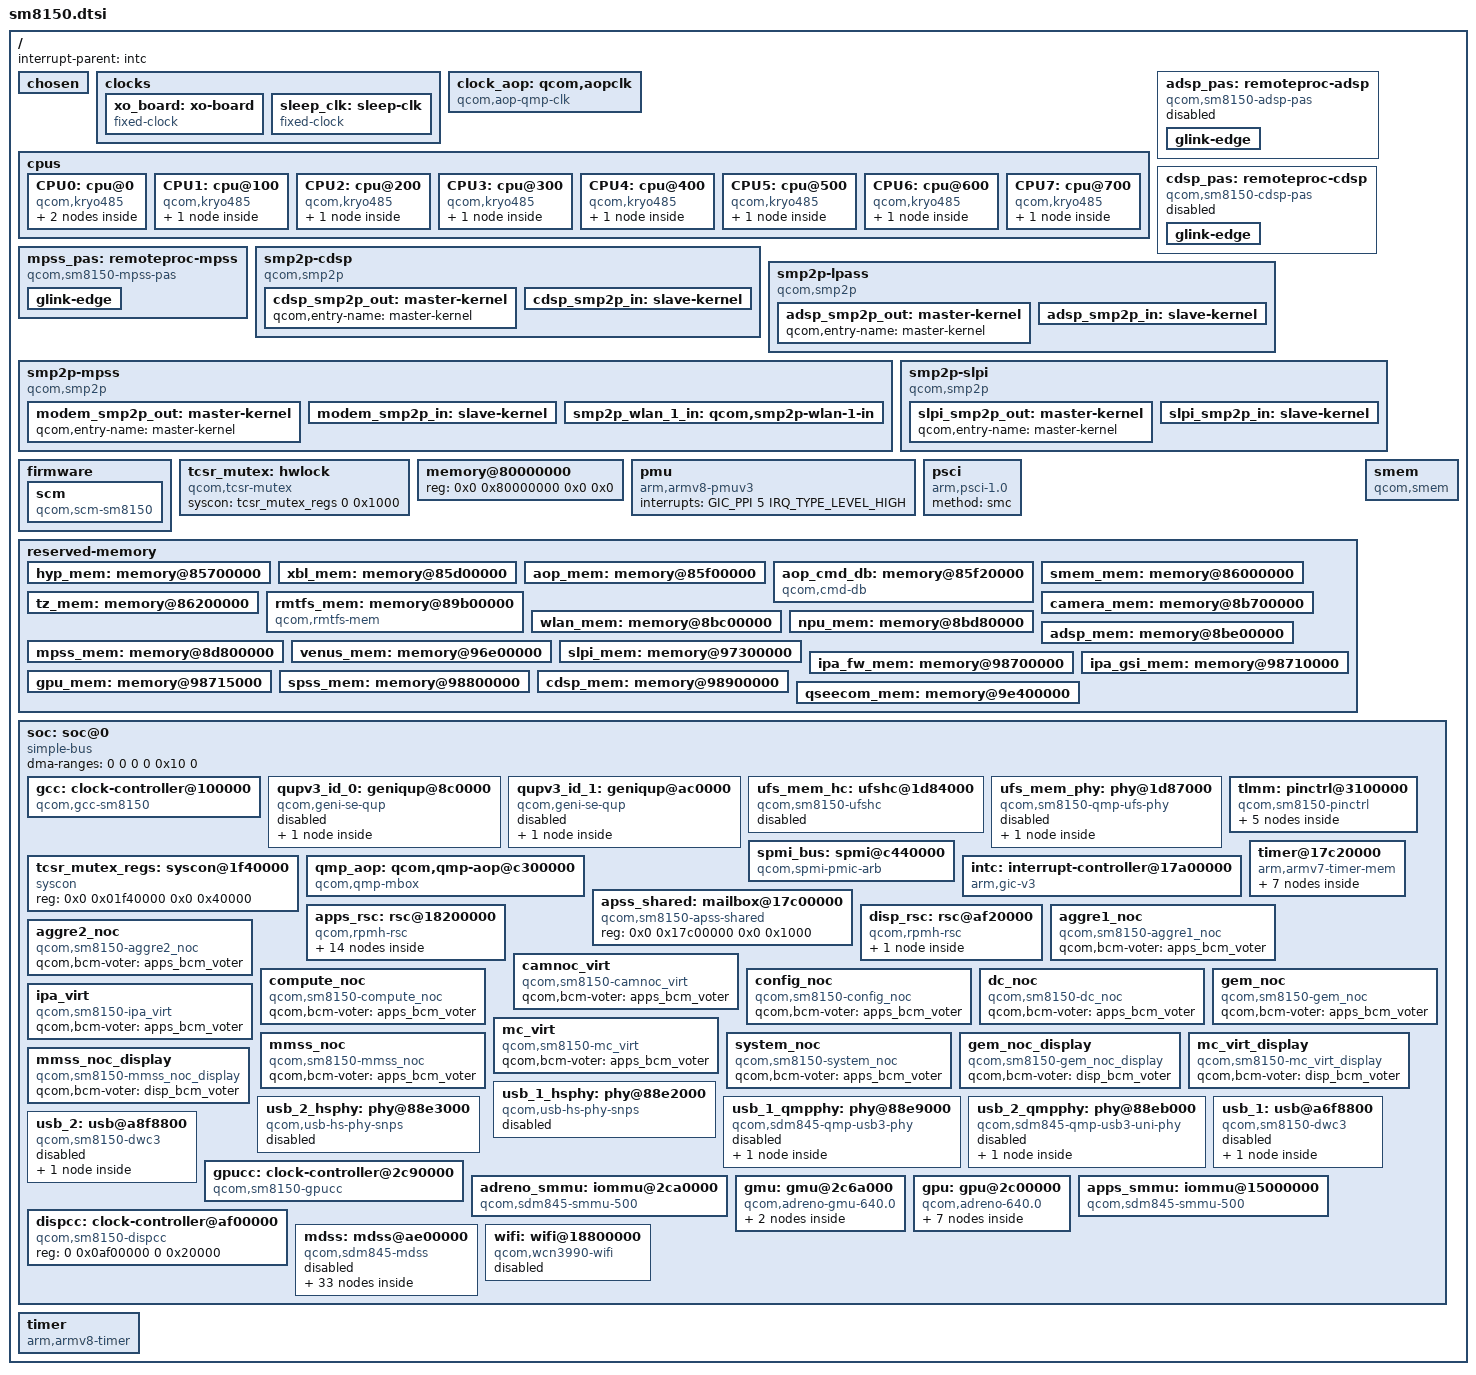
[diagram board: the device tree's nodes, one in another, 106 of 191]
// SPDX-License-Identifier: BSD-3-Clause
/*
 * Copyright (c) 2017-2019, The Linux Foundation. All rights reserved.
 * Copyright (c) 2019, Linaro Limited
 */

#include <dt-bindings/interrupt-controller/arm-gic.h>
#include <dt-bindings/soc/qcom,rpmh-rsc.h>
#include <dt-bindings/clock/qcom,rpmh.h>
#include <dt-bindings/clock/qcom,gcc-sm8150.h>
#include <dt-bindings/clock/qcom,gpucc-sm8150.h>
#include <dt-bindings/clock/qcom,dispcc-sm8150.h>
#include <dt-bindings/power/qcom-rpmpd.h>
#include <dt-bindings/interconnect/qcom,sm8150.h>

/ {
	interrupt-parent = <&intc>;

	#address-cells = <2>;
	#size-cells = <2>;

	chosen { };

	clocks {
		xo_board: xo-board {
			compatible = "fixed-clock";
			#clock-cells = <0>;
			clock-frequency = <38400000>;
			clock-output-names = "xo_board";
		};

		sleep_clk: sleep-clk {
			compatible = "fixed-clock";
			#clock-cells = <0>;
			clock-frequency = <32764>;
			clock-output-names = "sleep_clk";
		};
	};

	clock_aop: qcom,aopclk {
		compatible = "qcom,aop-qmp-clk";
		#clock-cells = <1>;
		mboxes = <&qmp_aop 0>;
		mbox-names = "qdss_clk";
	};

	cpus {
		#address-cells = <2>;
		#size-cells = <0>;

		CPU0: cpu@0 {
			device_type = "cpu";
			compatible = "qcom,kryo485";
			reg = <0x0 0x0>;
			enable-method = "psci";
			next-level-cache = <&L2_0>;
			L2_0: l2-cache {
				compatible = "cache";
				next-level-cache = <&L3_0>;
				L3_0: l3-cache {
				      compatible = "cache";
				};
			};
		};

		CPU1: cpu@100 {
			device_type = "cpu";
			compatible = "qcom,kryo485";
			reg = <0x0 0x100>;
			enable-method = "psci";
			next-level-cache = <&L2_100>;
			L2_100: l2-cache {
				compatible = "cache";
				next-level-cache = <&L3_0>;
			};

		};

		CPU2: cpu@200 {
			device_type = "cpu";
			compatible = "qcom,kryo485";
			reg = <0x0 0x200>;
			enable-method = "psci";
			next-level-cache = <&L2_200>;
			L2_200: l2-cache {
				compatible = "cache";
				next-level-cache = <&L3_0>;
			};
		};

		CPU3: cpu@300 {
			device_type = "cpu";
			compatible = "qcom,kryo485";
			reg = <0x0 0x300>;
			enable-method = "psci";
			next-level-cache = <&L2_300>;
			L2_300: l2-cache {
				compatible = "cache";
				next-level-cache = <&L3_0>;
			};
		};

		CPU4: cpu@400 {
			device_type = "cpu";
			compatible = "qcom,kryo485";
			reg = <0x0 0x400>;
			enable-method = "psci";
			next-level-cache = <&L2_400>;
			L2_400: l2-cache {
				compatible = "cache";
				next-level-cache = <&L3_0>;
			};
		};

		CPU5: cpu@500 {
			device_type = "cpu";
			compatible = "qcom,kryo485";
			reg = <0x0 0x500>;
			enable-method = "psci";
			next-level-cache = <&L2_500>;
			L2_500: l2-cache {
				compatible = "cache";
				next-level-cache = <&L3_0>;
			};
		};

		CPU6: cpu@600 {
			device_type = "cpu";
			compatible = "qcom,kryo485";
			reg = <0x0 0x600>;
			enable-method = "psci";
			next-level-cache = <&L2_600>;
			L2_600: l2-cache {
				compatible = "cache";
				next-level-cache = <&L3_0>;
			};
		};

		CPU7: cpu@700 {
			device_type = "cpu";
			compatible = "qcom,kryo485";
			reg = <0x0 0x700>;
			enable-method = "psci";
			next-level-cache = <&L2_700>;
			L2_700: l2-cache {
				compatible = "cache";
				next-level-cache = <&L3_0>;
			};
		};
	};

	adsp_pas: remoteproc-adsp {
		compatible = "qcom,sm8150-adsp-pas";

		interrupts-extended = <&intc GIC_SPI 162 IRQ_TYPE_EDGE_RISING>,
				      <&adsp_smp2p_in 0 IRQ_TYPE_EDGE_RISING>,
				      <&adsp_smp2p_in 1 IRQ_TYPE_EDGE_RISING>,
				      <&adsp_smp2p_in 2 IRQ_TYPE_EDGE_RISING>,
				      <&adsp_smp2p_in 3 IRQ_TYPE_EDGE_RISING>;
		interrupt-names = "wdog", "fatal", "ready",
				  "handover", "stop-ack";

		clocks = <&rpmhcc RPMH_CXO_CLK>;
		clock-names = "xo";

		memory-region = <&adsp_mem>;

		status = "disabled";

		qcom,smem-states = <&adsp_smp2p_out 0>;
		qcom,smem-state-names = "stop";

		glink-edge {
			interrupts = <GIC_SPI 156 IRQ_TYPE_EDGE_RISING>;
			label = "lpass";
			qcom,remote-pid = <2>;
			mboxes = <&apss_shared 8>;
		};
	};

	cdsp_pas: remoteproc-cdsp {
		compatible = "qcom,sm8150-cdsp-pas";

		interrupts-extended = <&intc GIC_SPI 578 IRQ_TYPE_EDGE_RISING>,
				      <&cdsp_smp2p_in 0 IRQ_TYPE_EDGE_RISING>,
				      <&cdsp_smp2p_in 1 IRQ_TYPE_EDGE_RISING>,
				      <&cdsp_smp2p_in 2 IRQ_TYPE_EDGE_RISING>,
				      <&cdsp_smp2p_in 3 IRQ_TYPE_EDGE_RISING>;
		interrupt-names = "wdog", "fatal", "ready",
				  "handover", "stop-ack";

		clocks = <&rpmhcc RPMH_CXO_CLK>;
		clock-names = "xo";

		memory-region = <&cdsp_mem>;

		status = "disabled";

		qcom,smem-states = <&cdsp_smp2p_out 0>;
		qcom,smem-state-names = "stop";

		glink-edge {
			interrupts = <GIC_SPI 574 IRQ_TYPE_EDGE_RISING>;
			label = "turing";
			qcom,remote-pid = <5>;
			mboxes = <&apss_shared 4>;
		};
	};

	mpss_pas: remoteproc-mpss {
		compatible = "qcom,sm8150-mpss-pas";

		interrupts-extended = <&intc GIC_SPI 266 IRQ_TYPE_EDGE_RISING>,
				      <&modem_smp2p_in 0 IRQ_TYPE_EDGE_RISING>,
				      <&modem_smp2p_in 1 IRQ_TYPE_EDGE_RISING>,
				      <&modem_smp2p_in 2 IRQ_TYPE_EDGE_RISING>,
				      <&modem_smp2p_in 3 IRQ_TYPE_EDGE_RISING>,
				      <&modem_smp2p_in 7 IRQ_TYPE_EDGE_RISING>;
		interrupt-names = "wdog", "fatal", "ready", "handover",
				  "stop-ack", "shutdown-ack";

		clocks = <&rpmhcc RPMH_CXO_CLK>;
		clock-names = "xo";

		memory-region = <&mpss_mem>;

		qcom,smem-states = <&modem_smp2p_out 0>;
		qcom,smem-state-names = "stop";

		glink-edge {
			interrupts = <GIC_SPI 449 IRQ_TYPE_EDGE_RISING>;
			label = "modem";
			qcom,remote-pid = <1>;
			mboxes = <&apss_shared 12>;
		};
	};

	smp2p-cdsp {
		compatible = "qcom,smp2p";
		qcom,smem = <94>, <432>;

		interrupts = <GIC_SPI 576 IRQ_TYPE_EDGE_RISING>;

		mboxes = <&apss_shared 6>;

		qcom,local-pid = <0>;
		qcom,remote-pid = <5>;

		cdsp_smp2p_out: master-kernel {
			qcom,entry-name = "master-kernel";
			#qcom,smem-state-cells = <1>;
		};

		cdsp_smp2p_in: slave-kernel {
			qcom,entry-name = "slave-kernel";

			interrupt-controller;
			#interrupt-cells = <2>;
		};
	};

	smp2p-lpass {
		compatible = "qcom,smp2p";
		qcom,smem = <443>, <429>;

		interrupts = <GIC_SPI 158 IRQ_TYPE_EDGE_RISING>;

		mboxes = <&apss_shared 10>;

		qcom,local-pid = <0>;
		qcom,remote-pid = <2>;

		adsp_smp2p_out: master-kernel {
			qcom,entry-name = "master-kernel";
			#qcom,smem-state-cells = <1>;
		};

		adsp_smp2p_in: slave-kernel {
			qcom,entry-name = "slave-kernel";

			interrupt-controller;
			#interrupt-cells = <2>;
		};
	};

	smp2p-mpss {
		compatible = "qcom,smp2p";
		qcom,smem = <435>, <428>;

		interrupts = <GIC_SPI 451 IRQ_TYPE_EDGE_RISING>;

		mboxes = <&apss_shared 14>;

		qcom,local-pid = <0>;
		qcom,remote-pid = <1>;

		modem_smp2p_out: master-kernel {
			qcom,entry-name = "master-kernel";
			#qcom,smem-state-cells = <1>;
		 };

		modem_smp2p_in: slave-kernel {
			qcom,entry-name = "slave-kernel";

			interrupt-controller;
			#interrupt-cells = <2>;
		};

		smp2p_wlan_1_in: qcom,smp2p-wlan-1-in {
			qcom,entry-name = "wlan";

			interrupt-controller;
			#interrupt-cells = <2>;
		};
	};

	smp2p-slpi {
		compatible = "qcom,smp2p";
		qcom,smem = <481>, <430>;

		interrupts = <GIC_SPI 172 IRQ_TYPE_EDGE_RISING>;

		mboxes = <&apss_shared 26>;

		qcom,local-pid = <0>;
		qcom,remote-pid = <3>;

		slpi_smp2p_out: master-kernel {
			qcom,entry-name = "master-kernel";
			#qcom,smem-state-cells = <1>;
		};

		slpi_smp2p_in: slave-kernel {
			qcom,entry-name = "slave-kernel";

			interrupt-controller;
			#interrupt-cells = <2>;
	       };
	};

	firmware {
		scm: scm {
			compatible = "qcom,scm-sm8150", "qcom,scm";
			#reset-cells = <1>;
		};
	};

	tcsr_mutex: hwlock {
		compatible = "qcom,tcsr-mutex";
		syscon = <&tcsr_mutex_regs 0 0x1000>;
		#hwlock-cells = <1>;
	};

	memory@80000000 {
		device_type = "memory";
		/* We expect the bootloader to fill in the size */
		reg = <0x0 0x80000000 0x0 0x0>;
	};

	pmu {
		compatible = "arm,armv8-pmuv3";
		interrupts = <GIC_PPI 5 IRQ_TYPE_LEVEL_HIGH>;
	};

	psci {
		compatible = "arm,psci-1.0";
		method = "smc";
	};

	reserved-memory {
		#address-cells = <2>;
		#size-cells = <2>;
		ranges;

		hyp_mem: memory@85700000 {
			reg = <0x0 0x85700000 0x0 0x600000>;
			no-map;
		};

		xbl_mem: memory@85d00000 {
			reg = <0x0 0x85d00000 0x0 0x140000>;
			no-map;
		};

		aop_mem: memory@85f00000 {
			reg = <0x0 0x85f00000 0x0 0x20000>;
			no-map;
		};

		aop_cmd_db: memory@85f20000 {
			compatible = "qcom,cmd-db";
			reg = <0x0 0x85f20000 0x0 0x20000>;
			no-map;
		};

		smem_mem: memory@86000000 {
			reg = <0x0 0x86000000 0x0 0x200000>;
			no-map;
		};

		tz_mem: memory@86200000 {
			reg = <0x0 0x86200000 0x0 0x3900000>;
			no-map;
		};

		rmtfs_mem: memory@89b00000 {
			compatible = "qcom,rmtfs-mem";
			reg = <0x0 0x89b00000 0x0 0x200000>;
			no-map;

			qcom,client-id = <1>;
			qcom,vmid = <15>;
		};

		camera_mem: memory@8b700000 {
			reg = <0x0 0x8b700000 0x0 0x500000>;
			no-map;
		};

		wlan_mem: memory@8bc00000 {
			reg = <0x0 0x8bc00000 0x0 0x180000>;
			no-map;
		};

		npu_mem: memory@8bd80000 {
			reg = <0x0 0x8bd80000 0x0 0x80000>;
			no-map;
		};

		adsp_mem: memory@8be00000 {
			reg = <0x0 0x8be00000 0x0 0x1a00000>;
			no-map;
		};

		mpss_mem: memory@8d800000 {
			reg = <0x0 0x8d800000 0x0 0x9600000>;
			no-map;
		};

		venus_mem: memory@96e00000 {
			reg = <0x0 0x96e00000 0x0 0x500000>;
			no-map;
		};

		slpi_mem: memory@97300000 {
			reg = <0x0 0x97300000 0x0 0x1400000>;
			no-map;
		};

		ipa_fw_mem: memory@98700000 {
			reg = <0x0 0x98700000 0x0 0x10000>;
			no-map;
		};

		ipa_gsi_mem: memory@98710000 {
			reg = <0x0 0x98710000 0x0 0x5000>;
			no-map;
		};

		gpu_mem: memory@98715000 {
			reg = <0x0 0x98715000 0x0 0x2000>;
			no-map;
		};

		spss_mem: memory@98800000 {
			reg = <0x0 0x98800000 0x0 0x100000>;
			no-map;
		};

		cdsp_mem: memory@98900000 {
			reg = <0x0 0x98900000 0x0 0x1400000>;
			no-map;
		};

		qseecom_mem: memory@9e400000 {
			reg = <0x0 0x9e400000 0x0 0x1400000>;
			no-map;
		};
	};

	smem {
		compatible = "qcom,smem";
		memory-region = <&smem_mem>;
		hwlocks = <&tcsr_mutex 3>;
	};

	soc: soc@0 {
		#address-cells = <2>;
		#size-cells = <2>;
		ranges = <0 0 0 0 0x10 0>;
		dma-ranges = <0 0 0 0 0x10 0>;
		compatible = "simple-bus";

		gcc: clock-controller@100000 {
			compatible = "qcom,gcc-sm8150";
			reg = <0x0 0x00100000 0x0 0x1f0000>;
			#clock-cells = <1>;
			#reset-cells = <1>;
			#power-domain-cells = <1>;
			clock-names = "bi_tcxo",
				      "sleep_clk";
			clocks = <&rpmhcc RPMH_CXO_CLK>,
				 <&sleep_clk>;
		};

		qupv3_id_0: geniqup@8c0000 {
			compatible = "qcom,geni-se-qup";
			reg = <0x0 0x008c0000 0x0 0x6000>;
			clock-names = "m-ahb", "s-ahb";
			clocks = <&gcc GCC_QUPV3_WRAP_0_M_AHB_CLK>,
				 <&gcc GCC_QUPV3_WRAP_0_S_AHB_CLK>;
			#address-cells = <2>;
			#size-cells = <2>;
			ranges;
			status = "disabled";
			//iommus = <&apps_smmu 0xc3 0x0>;

			i2c4: i2c@890000 {
				compatible = "qcom,geni-i2c";
				reg = <0 0x00890000 0 0x4000>;
				clock-names = "se";
				clocks = <&gcc GCC_QUPV3_WRAP0_S4_CLK>;
				pinctrl-names = "default";
				pinctrl-0 = <&qup_i2c4_default>;
				interrupts = <GIC_SPI 605 IRQ_TYPE_LEVEL_HIGH>;
				#address-cells = <1>;
				#size-cells = <0>;
				status = "disabled";
			};
		};

		qupv3_id_1: geniqup@ac0000 {
			compatible = "qcom,geni-se-qup";
			reg = <0x0 0x00ac0000 0x0 0x6000>;
			clock-names = "m-ahb", "s-ahb";
			clocks = <&gcc GCC_QUPV3_WRAP_1_M_AHB_CLK>,
				 <&gcc GCC_QUPV3_WRAP_1_S_AHB_CLK>;
			#address-cells = <2>;
			#size-cells = <2>;
			ranges;
			status = "disabled";

			uart2: serial@a90000 {
				compatible = "qcom,geni-debug-uart";
				reg = <0x0 0x00a90000 0x0 0x4000>;
				clock-names = "se";
				clocks = <&gcc GCC_QUPV3_WRAP1_S4_CLK>;
				interrupts = <GIC_SPI 357 IRQ_TYPE_LEVEL_HIGH>;
				status = "disabled";
			};
		};

		ufs_mem_hc: ufshc@1d84000 {
			compatible = "qcom,sm8150-ufshc", "qcom,ufshc",
				     "jedec,ufs-2.0";
			reg = <0 0x01d84000 0 0x2500>;
			interrupts = <GIC_SPI 265 IRQ_TYPE_LEVEL_HIGH>;
			phys = <&ufs_mem_phy_lanes>;
			phy-names = "ufsphy";
			lanes-per-direction = <2>;
			#reset-cells = <1>;
			resets = <&gcc GCC_UFS_PHY_BCR>;
			reset-names = "rst";

			clock-names =
				"core_clk",
				"bus_aggr_clk",
				"iface_clk",
				"core_clk_unipro",
				"ref_clk",
				"tx_lane0_sync_clk",
				"rx_lane0_sync_clk",
				"rx_lane1_sync_clk";
			clocks =
				<&gcc GCC_UFS_PHY_AXI_CLK>,
				<&gcc GCC_AGGRE_UFS_PHY_AXI_CLK>,
				<&gcc GCC_UFS_PHY_AHB_CLK>,
				<&gcc GCC_UFS_PHY_UNIPRO_CORE_CLK>,
				<&rpmhcc RPMH_CXO_CLK>,
				<&gcc GCC_UFS_PHY_TX_SYMBOL_0_CLK>,
				<&gcc GCC_UFS_PHY_RX_SYMBOL_0_CLK>,
				<&gcc GCC_UFS_PHY_RX_SYMBOL_1_CLK>;
			freq-table-hz =
				<37500000 300000000>,
				<0 0>,
				<0 0>,
				<37500000 300000000>,
				<0 0>,
				<0 0>,
				<0 0>,
				<0 0>;

			status = "disabled";
		};

		ufs_mem_phy: phy@1d87000 {
			compatible = "qcom,sm8150-qmp-ufs-phy";
			reg = <0 0x01d87000 0 0x18c>;
			#address-cells = <2>;
			#size-cells = <2>;
			ranges;
			clock-names = "ref",
				      "ref_aux";
			clocks = <&gcc GCC_UFS_MEM_CLKREF_CLK>,
				 <&gcc GCC_UFS_PHY_PHY_AUX_CLK>;

			resets = <&ufs_mem_hc 0>;
			reset-names = "ufsphy";
			status = "disabled";

			ufs_mem_phy_lanes: lanes@1d87400 {
				reg = <0 0x01d87400 0 0x108>,
				      <0 0x01d87600 0 0x1e0>,
				      <0 0x01d87c00 0 0x1dc>,
				      <0 0x01d87800 0 0x108>,
				      <0 0x01d87a00 0 0x1e0>;
				#phy-cells = <0>;
			};
		};

		tcsr_mutex_regs: syscon@1f40000 {
			compatible = "syscon";
			reg = <0x0 0x01f40000 0x0 0x40000>;
		};

		tlmm: pinctrl@3100000 {
			compatible = "qcom,sm8150-pinctrl";
			reg = <0x0 0x03100000 0x0 0x300000>,
			      <0x0 0x03500000 0x0 0x300000>,
			      <0x0 0x03900000 0x0 0x300000>,
			      <0x0 0x03D00000 0x0 0x300000>;
			reg-names = "west", "east", "north", "south";
			interrupts = <GIC_SPI 208 IRQ_TYPE_LEVEL_HIGH>;
			gpio-ranges = <&tlmm 0 0 175>;
			gpio-controller;
			#gpio-cells = <2>;
			interrupt-controller;
			#interrupt-cells = <2>;

			qup_i2c4_default: qup-i2c4-default {
				pinmux {
					pins = "gpio51", "gpio52";
					function = "qup4";
				};
			};

			fsa_usbc_ana_en: fsa_usbc_ana_en {
				mux {
					pins = "gpio100";
					function = "gpio";
				};

				config {
					pins = "gpio100";
					drive-strength = <2>;
					bias-disable;
					output-low;
				};
			};
		};

#if 0
		aoss_qmp: power-controller@c300000 {
			compatible = "qcom,sm8150-aoss-qmp";
			reg = <0x0 0x0c300000 0x0 0x100000>;
			interrupts = <GIC_SPI 389 IRQ_TYPE_EDGE_RISING>;
			mboxes = <&apss_shared 0>;

			#clock-cells = <0>;
			#power-domain-cells = <1>;
		};
#else
		qmp_aop: qcom,qmp-aop@c300000 {
			compatible = "qcom,qmp-mbox";
			reg = <0x0 0xc300000 0x0 0x1000>, <0x0 0x17c0000C 0x0 0x4>;
			reg-names = "msgram", "irq-reg-base";
			qcom,irq-mask = <0x1>;
			interrupts = <GIC_SPI 389 IRQ_TYPE_EDGE_RISING>;

			label = "aop";
			qcom,early-boot;
			priority = <0>;
			mbox-desc-offset = <0x0>;
			#mbox-cells = <1>;
		};
#endif

		spmi_bus: spmi@c440000 {
			compatible = "qcom,spmi-pmic-arb";
			reg = <0x0 0x0c440000 0x0 0x0001100>,
			      <0x0 0x0c600000 0x0 0x2000000>,
			      <0x0 0x0e600000 0x0 0x0100000>,
			      <0x0 0x0e700000 0x0 0x00a0000>,
			      <0x0 0x0c40a000 0x0 0x0026000>;
			reg-names = "core", "chnls", "obsrvr", "intr", "cnfg";
			interrupt-names = "periph_irq";
			interrupts = <GIC_SPI 481 IRQ_TYPE_LEVEL_HIGH>;
			qcom,ee = <0>;
			qcom,channel = <0>;
			#address-cells = <2>;
			#size-cells = <0>;
			interrupt-controller;
			#interrupt-cells = <4>;
			cell-index = <0>;
		};

		intc: interrupt-controller@17a00000 {
			compatible = "arm,gic-v3";
			interrupt-controller;
			#interrupt-cells = <3>;
			reg = <0x0 0x17a00000 0x0 0x10000>,	/* GICD */
			      <0x0 0x17a60000 0x0 0x100000>;	/* GICR * 8 */
			interrupts = <GIC_PPI 9 IRQ_TYPE_LEVEL_HIGH>;
		};

		apss_shared: mailbox@17c00000 {
			compatible = "qcom,sm8150-apss-shared";
			reg = <0x0 0x17c00000 0x0 0x1000>;
			#mbox-cells = <1>;
		};

		timer@17c20000 {
			#address-cells = <2>;
			#size-cells = <2>;
			ranges;
			compatible = "arm,armv7-timer-mem";
			reg = <0x0 0x17c20000 0x0 0x1000>;
			clock-frequency = <19200000>;

			frame@17c21000{
				frame-number = <0>;
				interrupts = <GIC_SPI 8 IRQ_TYPE_LEVEL_HIGH>,
					     <GIC_SPI 6 IRQ_TYPE_LEVEL_HIGH>;
				reg = <0x0 0x17c21000 0x0 0x1000>,
				      <0x0 0x17c22000 0x0 0x1000>;
			};

			frame@17c23000 {
				frame-number = <1>;
				interrupts = <GIC_SPI 9 IRQ_TYPE_LEVEL_HIGH>;
				reg = <0x0 0x17c23000 0x0 0x1000>;
				status = "disabled";
			};

			frame@17c25000 {
				frame-number = <2>;
				interrupts = <GIC_SPI 10 IRQ_TYPE_LEVEL_HIGH>;
				reg = <0x0 0x17c25000 0x0 0x1000>;
				status = "disabled";
			};

			frame@17c27000 {
				frame-number = <3>;
				interrupts = <GIC_SPI 11 IRQ_TYPE_LEVEL_HIGH>;
				reg = <0x0 0x17c26000 0x0 0x1000>;
				status = "disabled";
			};

			frame@17c29000 {
				frame-number = <4>;
				interrupts = <GIC_SPI 12 IRQ_TYPE_LEVEL_HIGH>;
				reg = <0x0 0x17c29000 0x0 0x1000>;
				status = "disabled";
			};

			frame@17c2b000 {
				frame-number = <5>;
				interrupts = <GIC_SPI 13 IRQ_TYPE_LEVEL_HIGH>;
				reg = <0x0 0x17c2b000 0x0 0x1000>;
				status = "disabled";
			};

			frame@17c2d000 {
				frame-number = <6>;
				interrupts = <GIC_SPI 14 IRQ_TYPE_LEVEL_HIGH>;
				reg = <0x0 0x17c2d000 0x0 0x1000>;
				status = "disabled";
			};
		};

		apps_rsc: rsc@18200000 {
			label = "apps_rsc";
			compatible = "qcom,rpmh-rsc";
			reg = <0x0 0x18200000 0x0 0x10000>,
			      <0x0 0x18210000 0x0 0x10000>,
			      <0x0 0x18220000 0x0 0x10000>;
			reg-names = "drv-0", "drv-1", "drv-2";
			interrupts = <GIC_SPI 3 IRQ_TYPE_LEVEL_HIGH>,
				     <GIC_SPI 4 IRQ_TYPE_LEVEL_HIGH>,
				     <GIC_SPI 5 IRQ_TYPE_LEVEL_HIGH>;
			qcom,tcs-offset = <0xd00>;
			qcom,drv-id = <2>;
			qcom,tcs-config = <ACTIVE_TCS  2>,
					  <SLEEP_TCS   1>,
					  <WAKE_TCS    1>,
					  <CONTROL_TCS 0>;

			rpmhcc: clock-controller {
				compatible = "qcom,sm8150-rpmh-clk";
				#clock-cells = <1>;
				clock-names = "xo";
				clocks = <&xo_board>;
			};

			rpmhpd: power-controller {
				compatible = "qcom,sm8150-rpmhpd";
				#power-domain-cells = <1>;
				operating-points-v2 = <&rpmhpd_opp_table>;

				rpmhpd_opp_table: opp-table {
					compatible = "operating-points-v2";

					rpmhpd_opp_ret: opp1 {
						opp-level = <RPMH_REGULATOR_LEVEL_RETENTION>;
					};

					rpmhpd_opp_min_svs: opp2 {
						opp-level = <RPMH_REGULATOR_LEVEL_MIN_SVS>;
					};

					rpmhpd_opp_low_svs: opp3 {
						opp-level = <RPMH_REGULATOR_LEVEL_LOW_SVS>;
					};

					rpmhpd_opp_svs: opp4 {
						opp-level = <RPMH_REGULATOR_LEVEL_SVS>;
					};

					rpmhpd_opp_svs_l1: opp5 {
						opp-level = <RPMH_REGULATOR_LEVEL_SVS_L1>;
					};

					rpmhpd_opp_nom: opp6 {
						opp-level = <RPMH_REGULATOR_LEVEL_NOM>;
					};

					rpmhpd_opp_nom_l1: opp7 {
						opp-level = <RPMH_REGULATOR_LEVEL_NOM_L1>;
					};

					rpmhpd_opp_nom_l2: opp8 {
						opp-level = <RPMH_REGULATOR_LEVEL_NOM_L2>;
					};

					rpmhpd_opp_turbo: opp9 {
						opp-level = <RPMH_REGULATOR_LEVEL_TURBO>;
					};

					rpmhpd_opp_turbo_l1: opp10 {
						opp-level = <RPMH_REGULATOR_LEVEL_TURBO_L1>;
					};
				};
			};

			apps_bcm_voter: bcm_voter {
				compatible = "qcom,sm8150-bcm-voter";
			};
		};

		disp_rsc: rsc@af20000 {
			label = "display_rsc";
			compatible = "qcom,rpmh-rsc";
			reg = <0x0 0xaf20000 0x0 0x10000>;
			reg-names = "drv-0";
			interrupts = <GIC_SPI 129 IRQ_TYPE_LEVEL_HIGH>;
			qcom,tcs-offset = <0x1c00>;
			qcom,drv-id = <0>;
			qcom,tcs-config = <SLEEP_TCS   1>,
					  <WAKE_TCS    1>,
					  <ACTIVE_TCS  2>,
					  <CONTROL_TCS 0>;

			disp_bcm_voter: bcm_voter {
				compatible = "qcom,sm8150-bcm-voter";
			};
		};

		aggre1_noc: aggre1_noc {
			compatible = "qcom,sm8150-aggre1_noc";
			#interconnect-cells = <1>;
			qcom,bcm-voter = <&apps_bcm_voter>;
		};

		aggre2_noc: aggre2_noc {
			compatible = "qcom,sm8150-aggre2_noc";
			#interconnect-cells = <1>;
			qcom,bcm-voter = <&apps_bcm_voter>;
		};

		camnoc_virt: camnoc_virt {
			compatible = "qcom,sm8150-camnoc_virt";
			#interconnect-cells = <1>;
			qcom,bcm-voter = <&apps_bcm_voter>;
		};

		compute_noc: compute_noc {
			compatible = "qcom,sm8150-compute_noc";
			#interconnect-cells = <1>;
			qcom,bcm-voter = <&apps_bcm_voter>;
		};

		config_noc: config_noc {
			compatible = "qcom,sm8150-config_noc";
			#interconnect-cells = <1>;
			qcom,bcm-voter = <&apps_bcm_voter>;
		};

		dc_noc: dc_noc {
			compatible = "qcom,sm8150-dc_noc";
			#interconnect-cells = <1>;
			qcom,bcm-voter = <&apps_bcm_voter>;
		};

		gem_noc: gem_noc {
			compatible = "qcom,sm8150-gem_noc";
			#interconnect-cells = <1>;
			qcom,bcm-voter = <&apps_bcm_voter>;
		};

		ipa_virt: ipa_virt {
			compatible = "qcom,sm8150-ipa_virt";
			#interconnect-cells = <1>;
			qcom,bcm-voter = <&apps_bcm_voter>;
		};

		mc_virt: mc_virt {
			compatible = "qcom,sm8150-mc_virt";
			#interconnect-cells = <1>;
			qcom,bcm-voter = <&apps_bcm_voter>;
		};

		mmss_noc: mmss_noc {
			compatible = "qcom,sm8150-mmss_noc";
			#interconnect-cells = <1>;
			qcom,bcm-voter = <&apps_bcm_voter>;
		};

		system_noc: system_noc {
			compatible = "qcom,sm8150-system_noc";
			#interconnect-cells = <1>;
			qcom,bcm-voter = <&apps_bcm_voter>;
		};

		gem_noc_display: gem_noc_display {
			compatible = "qcom,sm8150-gem_noc_display";
			#interconnect-cells = <1>;
			qcom,bcm-voter = <&disp_bcm_voter>;
		};

		mc_virt_display: mc_virt_display {
			compatible = "qcom,sm8150-mc_virt_display";
			#interconnect-cells = <1>;
			qcom,bcm-voter = <&disp_bcm_voter>;
		};

		mmss_noc_display: mmss_noc_display {
			compatible = "qcom,sm8150-mmss_noc_display";
			#interconnect-cells = <1>;
			qcom,bcm-voter = <&disp_bcm_voter>;
		};

		usb_1_hsphy: phy@88e2000 {
			compatible = "qcom,usb-hs-phy-snps";
			reg = <0 0x088e2000 0 0x110>;
			status = "disabled";
			#phy-cells = <0>;

			clocks = <&rpmhcc RPMH_CXO_CLK>;
			clock-names = "ref";

			resets = <&gcc GCC_QUSB2PHY_PRIM_BCR>;
			reset-names = "por";
		};

		usb_2_hsphy: phy@88e3000 {
			compatible = "qcom,usb-hs-phy-snps";
			reg = <0 0x088e3000 0 0x110>;
			status = "disabled";
			#phy-cells = <0>;

			clocks = <&rpmhcc RPMH_CXO_CLK>;
			clock-names = "ref";

			resets = <&gcc GCC_QUSB2PHY_SEC_BCR>;
			reset-names = "por";
		};

		usb_1_qmpphy: phy@88e9000 {
			compatible = "qcom,sdm845-qmp-usb3-phy";
			reg = <0 0x088e9000 0 0x18c>,
			      <0 0x088e8000 0 0x10>;
			reg-names = "reg-base", "dp_com";
			status = "disabled";
			#clock-cells = <1>;
			#address-cells = <2>;
			#size-cells = <2>;
			ranges;

			clocks = <&gcc GCC_USB3_PRIM_PHY_AUX_CLK>,
				 <&xo_board>,
				 <&gcc GCC_USB3_PRIM_CLKREF_CLK>,
				 <&gcc GCC_USB3_PRIM_PHY_COM_AUX_CLK>;
			clock-names = "aux", "cfg_ahb", "ref", "com_aux";

			resets = <&gcc GCC_USB3_DP_PHY_PRIM_BCR>,
				 <&gcc GCC_USB3_PHY_PRIM_BCR>;
			reset-names = "phy", "common";

			usb_1_ssphy: lanes@88e9200 {
				reg = <0 0x088e9200 0 0x128>,
				      <0 0x088e9400 0 0x200>,
				      <0 0x088e9c00 0 0x218>,
				      <0 0x088e9600 0 0x128>,
				      <0 0x088e9800 0 0x200>,
				      <0 0x088e9a00 0 0x100>;
				#phy-cells = <0>;
				clocks = <&gcc GCC_USB3_PRIM_PHY_PIPE_CLK>;
				clock-names = "pipe0";
				clock-output-names = "usb3_phy_pipe_clk_src";
			};
		};

		usb_2_qmpphy: phy@88eb000 {
			compatible = "qcom,sdm845-qmp-usb3-uni-phy";
			reg = <0 0x088eb000 0 0x18c>;
			status = "disabled";
			#clock-cells = <1>;
			#address-cells = <2>;
			#size-cells = <2>;
			ranges;

			clocks = <&gcc GCC_USB3_SEC_PHY_AUX_CLK>,
				 <&xo_board>,
				 <&gcc GCC_USB3_SEC_CLKREF_CLK>,
				 <&gcc GCC_USB3_SEC_PHY_COM_AUX_CLK>;
			clock-names = "aux", "cfg_ahb", "ref", "com_aux";

			resets = <&gcc GCC_USB3PHY_PHY_SEC_BCR>,
				 <&gcc GCC_USB3_PHY_SEC_BCR>;
			reset-names = "phy", "common";

			usb_2_ssphy: lane@88eb200 {
				reg = <0 0x088eb200 0 0x128>,
				      <0 0x088eb400 0 0x1fc>,
				      <0 0x088eb800 0 0x218>,
				      <0 0x088eb600 0 0x70>;
				#phy-cells = <0>;
				clocks = <&gcc GCC_USB3_SEC_PHY_PIPE_CLK>;
				clock-names = "pipe0";
				clock-output-names = "usb3_uni_phy_pipe_clk_src";
			};
		};

		usb_1: usb@a6f8800 {
			compatible = "qcom,sm8150-dwc3", "qcom,dwc3";
			reg = <0 0x0a6f8800 0 0x400>;
			status = "disabled";
			#address-cells = <2>;
			#size-cells = <2>;
			ranges;
			dma-ranges;

			clocks = <&gcc GCC_CFG_NOC_USB3_PRIM_AXI_CLK>,
				 <&gcc GCC_USB30_PRIM_MASTER_CLK>,
				 <&gcc GCC_AGGRE_USB3_PRIM_AXI_CLK>,
				 <&gcc GCC_USB30_PRIM_MOCK_UTMI_CLK>,
				 <&gcc GCC_USB30_PRIM_SLEEP_CLK>;
			clock-names = "cfg_noc", "core", "iface", "mock_utmi",
				      "sleep";

			assigned-clocks = <&gcc GCC_USB30_PRIM_MOCK_UTMI_CLK>,
					  <&gcc GCC_USB30_PRIM_MASTER_CLK>;
			assigned-clock-rates = <19200000>, <200000000>;

			interrupts = <GIC_SPI 131 IRQ_TYPE_LEVEL_HIGH>,
				     <GIC_SPI 486 IRQ_TYPE_LEVEL_HIGH>,
				     <GIC_SPI 488 IRQ_TYPE_LEVEL_HIGH>,
				     <GIC_SPI 489 IRQ_TYPE_LEVEL_HIGH>;
			interrupt-names = "hs_phy_irq", "ss_phy_irq",
					  "dm_hs_phy_irq", "dp_hs_phy_irq";

			power-domains = <&gcc USB30_PRIM_GDSC>;

			resets = <&gcc GCC_USB30_PRIM_BCR>;

			usb_1_dwc3: dwc3@a600000 {
				compatible = "snps,dwc3";
				reg = <0 0x0a600000 0 0xcd00>;
				interrupts = <GIC_SPI 133 IRQ_TYPE_LEVEL_HIGH>;
				iommus = <&apps_smmu 0x140 0>;
				phys = <&usb_1_hsphy>, <&usb_1_ssphy>;
				phy-names = "usb2-phy", "usb3-phy";
			};
		};

		usb_2: usb@a8f8800 {
			compatible = "qcom,sm8150-dwc3", "qcom,dwc3";
			reg = <0 0x0a8f8800 0 0x400>;
			status = "disabled";
			#address-cells = <2>;
			#size-cells = <2>;
			ranges;
			dma-ranges;

			clocks = <&gcc GCC_CFG_NOC_USB3_SEC_AXI_CLK>,
				 <&gcc GCC_USB30_SEC_MASTER_CLK>,
				 <&gcc GCC_AGGRE_USB3_SEC_AXI_CLK>,
				 <&gcc GCC_USB30_SEC_MOCK_UTMI_CLK>,
				 <&gcc GCC_USB30_SEC_SLEEP_CLK>;
			clock-names = "cfg_noc", "core", "iface", "mock_utmi",
				      "sleep";

			assigned-clocks = <&gcc GCC_USB30_SEC_MOCK_UTMI_CLK>,
					  <&gcc GCC_USB30_SEC_MASTER_CLK>;
			assigned-clock-rates = <19200000>, <200000000>;

			interrupts = <GIC_SPI 136 IRQ_TYPE_LEVEL_HIGH>,
				     <GIC_SPI 487 IRQ_TYPE_LEVEL_HIGH>,
				     <GIC_SPI 490 IRQ_TYPE_LEVEL_HIGH>,
				     <GIC_SPI 491 IRQ_TYPE_LEVEL_HIGH>;
			interrupt-names = "hs_phy_irq", "ss_phy_irq",
					  "dm_hs_phy_irq", "dp_hs_phy_irq";

			power-domains = <&gcc USB30_SEC_GDSC>;

			resets = <&gcc GCC_USB30_SEC_BCR>;

			usb_2_dwc3: dwc3@a800000 {
				compatible = "snps,dwc3";
				reg = <0 0x0a800000 0 0xcd00>;
				interrupts = <GIC_SPI 138 IRQ_TYPE_LEVEL_HIGH>;
				iommus = <&apps_smmu 0x160 0>;
				phys = <&usb_2_hsphy>, <&usb_2_ssphy>;
				phy-names = "usb2-phy", "usb3-phy";
			};
		};

		gpucc: clock-controller@2c90000 {
			compatible = "qcom,sm8150-gpucc";
			reg = <0 0x2c90000 0 0x9000>;
			#clock-cells = <1>;
			#reset-cells = <1>;
			#power-domain-cells = <1>;
			clocks = <&rpmhcc RPMH_CXO_CLK>;
			clock-names = "xo";
		};

		adreno_smmu: iommu@2ca0000 {
			compatible = "qcom,sdm845-smmu-500", "arm,mmu-500";
			reg = <0 0x2ca0000 0 0x10000>;
			#iommu-cells = <2>;
			#global-interrupts = <1>;
			interrupts = <GIC_SPI 674 IRQ_TYPE_LEVEL_HIGH>,
				<GIC_SPI 681 IRQ_TYPE_LEVEL_HIGH>,
				<GIC_SPI 682 IRQ_TYPE_LEVEL_HIGH>,
				<GIC_SPI 683 IRQ_TYPE_LEVEL_HIGH>,
				<GIC_SPI 684 IRQ_TYPE_LEVEL_HIGH>,
				<GIC_SPI 685 IRQ_TYPE_LEVEL_HIGH>,
				<GIC_SPI 686 IRQ_TYPE_LEVEL_HIGH>,
				<GIC_SPI 687 IRQ_TYPE_LEVEL_HIGH>,
				<GIC_SPI 688 IRQ_TYPE_LEVEL_HIGH>;
			clocks = <&gcc GCC_GPU_MEMNOC_GFX_CLK>,
			         <&gcc GCC_GPU_SNOC_DVM_GFX_CLK>,
					 <&gpucc GPU_CC_AHB_CLK>;
			clock-names = "bus", "iface", "ahb";

			power-domains = <&gpucc GPU_CX_GDSC>;
		};

		gmu: gmu@2c6a000 {
			compatible="qcom,adreno-gmu-640.0", "qcom,adreno-gmu";

			reg = <0 0x2c6a000 0 0x30000>,
			      <0 0xb280000 0 0x10000>,
			      <0 0xb480000 0 0x10000>;
			reg-names = "gmu", "gmu_pdc", "gmu_pdc_seq";

			interrupts = <GIC_SPI 304 IRQ_TYPE_LEVEL_HIGH>,
				     <GIC_SPI 305 IRQ_TYPE_LEVEL_HIGH>;
			interrupt-names = "hfi", "gmu";

			clocks = <&gpucc GPU_CC_CX_GMU_CLK>,
			         <&gpucc GPU_CC_CXO_CLK>,
				 <&gcc GCC_DDRSS_GPU_AXI_CLK>,
				 <&gcc GCC_GPU_MEMNOC_GFX_CLK>,
				 <&gpucc GPU_CC_AHB_CLK>;
			clock-names = "gmu", "cxo", "axi", "memnoc", "ahb";

			power-domains = <&gpucc GPU_CX_GDSC>,
					<&gpucc GPU_GX_GDSC>;
			power-domain-names = "cx", "gx";

			iommus = <&adreno_smmu 5 0x400>;

			operating-points-v2 = <&gmu_opp_table>;

			gmu_opp_table: opp-table {
				compatible = "operating-points-v2";

				opp-200000000 {
					opp-hz = /bits/ 64 <200000000>;
					opp-level = <RPMH_REGULATOR_LEVEL_MIN_SVS>;
				};
			};
		};

		gpu: gpu@2c00000 {
			compatible = "qcom,adreno-640.0", "qcom,adreno";
			#stream-id-cells = <16>;

			reg = <0 0x2c00000 0 0x40000>;
			reg-names = "kgsl_3d0_reg_memory";

			interrupts = <GIC_SPI 300 IRQ_TYPE_LEVEL_HIGH>;

			iommus = <&adreno_smmu 0 0x401>;

			operating-points-v2 = <&gpu_opp_table>;

			qcom,gmu = <&gmu>;

			zap-shader {
				memory-region = <&gpu_mem>;
			};

			/* TODO: these are sm8150v2 freqs */
			gpu_opp_table: opp-table {
				compatible = "operating-points-v2";

				opp-257000000 {
					opp-hz = /bits/ 64 <257000000>;
					opp-level = <RPMH_REGULATOR_LEVEL_LOW_SVS>;
				};

				opp-345000000 {
					opp-hz = /bits/ 64 <345000000>;
					opp-level = <RPMH_REGULATOR_LEVEL_SVS>;
				};

				opp-427000000 {
					opp-hz = /bits/ 64 <427000000>;
					opp-level = <RPMH_REGULATOR_LEVEL_SVS_L1>;
				};

				/*opp-499200000 {
					opp-hz = /bits/ 64 <499200000>;
					opp-level = <RPMH_REGULATOR_LEVEL_NOM>;
				};*/

				opp-585000000 {
					opp-hz = /bits/ 64 <585000000>;
					opp-level = <RPMH_REGULATOR_LEVEL_NOM>;
				};

				opp-675000000 {
					opp-hz = /bits/ 64 <675000000>;
					opp-level = <RPMH_REGULATOR_LEVEL_NOM_L1>;
				};
			};
		};

		apps_smmu: iommu@15000000 {
			compatible = "qcom,sdm845-smmu-500", "arm,mmu-500";
			reg = <0 0x15000000 0 0x100000>;
			#iommu-cells = <2>;
			qcom,smmu-500-fw-impl-safe-errata;
			#global-interrupts = <1>;
			interrupts = <GIC_SPI 65 IRQ_TYPE_LEVEL_HIGH>,
					<GIC_SPI 97 IRQ_TYPE_LEVEL_HIGH>,
					<GIC_SPI 98 IRQ_TYPE_LEVEL_HIGH>,
					<GIC_SPI 99 IRQ_TYPE_LEVEL_HIGH>,
					<GIC_SPI 100 IRQ_TYPE_LEVEL_HIGH>,
					<GIC_SPI 101 IRQ_TYPE_LEVEL_HIGH>,
					<GIC_SPI 102 IRQ_TYPE_LEVEL_HIGH>,
					<GIC_SPI 103 IRQ_TYPE_LEVEL_HIGH>,
					<GIC_SPI 104 IRQ_TYPE_LEVEL_HIGH>,
					<GIC_SPI 105 IRQ_TYPE_LEVEL_HIGH>,
					<GIC_SPI 106 IRQ_TYPE_LEVEL_HIGH>,
					<GIC_SPI 107 IRQ_TYPE_LEVEL_HIGH>,
					<GIC_SPI 108 IRQ_TYPE_LEVEL_HIGH>,
					<GIC_SPI 109 IRQ_TYPE_LEVEL_HIGH>,
					<GIC_SPI 110 IRQ_TYPE_LEVEL_HIGH>,
					<GIC_SPI 111 IRQ_TYPE_LEVEL_HIGH>,
					<GIC_SPI 112 IRQ_TYPE_LEVEL_HIGH>,
					<GIC_SPI 113 IRQ_TYPE_LEVEL_HIGH>,
					<GIC_SPI 114 IRQ_TYPE_LEVEL_HIGH>,
					<GIC_SPI 115 IRQ_TYPE_LEVEL_HIGH>,
					<GIC_SPI 116 IRQ_TYPE_LEVEL_HIGH>,
					<GIC_SPI 117 IRQ_TYPE_LEVEL_HIGH>,
					<GIC_SPI 118 IRQ_TYPE_LEVEL_HIGH>,
					<GIC_SPI 181 IRQ_TYPE_LEVEL_HIGH>,
					<GIC_SPI 182 IRQ_TYPE_LEVEL_HIGH>,
					<GIC_SPI 183 IRQ_TYPE_LEVEL_HIGH>,
					<GIC_SPI 184 IRQ_TYPE_LEVEL_HIGH>,
					<GIC_SPI 185 IRQ_TYPE_LEVEL_HIGH>,
					<GIC_SPI 186 IRQ_TYPE_LEVEL_HIGH>,
					<GIC_SPI 187 IRQ_TYPE_LEVEL_HIGH>,
					<GIC_SPI 188 IRQ_TYPE_LEVEL_HIGH>,
					<GIC_SPI 189 IRQ_TYPE_LEVEL_HIGH>,
					<GIC_SPI 190 IRQ_TYPE_LEVEL_HIGH>,
					<GIC_SPI 191 IRQ_TYPE_LEVEL_HIGH>,
					<GIC_SPI 192 IRQ_TYPE_LEVEL_HIGH>,
					<GIC_SPI 315 IRQ_TYPE_LEVEL_HIGH>,
					<GIC_SPI 316 IRQ_TYPE_LEVEL_HIGH>,
					<GIC_SPI 317 IRQ_TYPE_LEVEL_HIGH>,
					<GIC_SPI 318 IRQ_TYPE_LEVEL_HIGH>,
					<GIC_SPI 319 IRQ_TYPE_LEVEL_HIGH>,
					<GIC_SPI 320 IRQ_TYPE_LEVEL_HIGH>,
					<GIC_SPI 321 IRQ_TYPE_LEVEL_HIGH>,
					<GIC_SPI 322 IRQ_TYPE_LEVEL_HIGH>,
					<GIC_SPI 323 IRQ_TYPE_LEVEL_HIGH>,
					<GIC_SPI 324 IRQ_TYPE_LEVEL_HIGH>,
					<GIC_SPI 325 IRQ_TYPE_LEVEL_HIGH>,
					<GIC_SPI 326 IRQ_TYPE_LEVEL_HIGH>,
					<GIC_SPI 327 IRQ_TYPE_LEVEL_HIGH>,
					<GIC_SPI 328 IRQ_TYPE_LEVEL_HIGH>,
					<GIC_SPI 329 IRQ_TYPE_LEVEL_HIGH>,
					<GIC_SPI 330 IRQ_TYPE_LEVEL_HIGH>,
					<GIC_SPI 331 IRQ_TYPE_LEVEL_HIGH>,
					<GIC_SPI 332 IRQ_TYPE_LEVEL_HIGH>,
					<GIC_SPI 333 IRQ_TYPE_LEVEL_HIGH>,
					<GIC_SPI 334 IRQ_TYPE_LEVEL_HIGH>,
					<GIC_SPI 335 IRQ_TYPE_LEVEL_HIGH>,
					<GIC_SPI 336 IRQ_TYPE_LEVEL_HIGH>,
					<GIC_SPI 337 IRQ_TYPE_LEVEL_HIGH>,
					<GIC_SPI 338 IRQ_TYPE_LEVEL_HIGH>,
					<GIC_SPI 339 IRQ_TYPE_LEVEL_HIGH>,
					<GIC_SPI 340 IRQ_TYPE_LEVEL_HIGH>,
					<GIC_SPI 341 IRQ_TYPE_LEVEL_HIGH>,
					<GIC_SPI 342 IRQ_TYPE_LEVEL_HIGH>,
					<GIC_SPI 343 IRQ_TYPE_LEVEL_HIGH>,
					<GIC_SPI 344 IRQ_TYPE_LEVEL_HIGH>,
					<GIC_SPI 345 IRQ_TYPE_LEVEL_HIGH>,
					<GIC_SPI 395 IRQ_TYPE_LEVEL_HIGH>,
					<GIC_SPI 396 IRQ_TYPE_LEVEL_HIGH>,
					<GIC_SPI 397 IRQ_TYPE_LEVEL_HIGH>,
					<GIC_SPI 398 IRQ_TYPE_LEVEL_HIGH>,
					<GIC_SPI 399 IRQ_TYPE_LEVEL_HIGH>,
					<GIC_SPI 400 IRQ_TYPE_LEVEL_HIGH>,
					<GIC_SPI 401 IRQ_TYPE_LEVEL_HIGH>,
					<GIC_SPI 402 IRQ_TYPE_LEVEL_HIGH>,
					<GIC_SPI 403 IRQ_TYPE_LEVEL_HIGH>,
					<GIC_SPI 404 IRQ_TYPE_LEVEL_HIGH>,
					<GIC_SPI 405 IRQ_TYPE_LEVEL_HIGH>,
					<GIC_SPI 406 IRQ_TYPE_LEVEL_HIGH>,
					<GIC_SPI 407 IRQ_TYPE_LEVEL_HIGH>,
					<GIC_SPI 408 IRQ_TYPE_LEVEL_HIGH>,
					<GIC_SPI 409 IRQ_TYPE_LEVEL_HIGH>;
		};

		dispcc: clock-controller@af00000 {
			compatible = "qcom,sm8150-dispcc";
			reg = <0 0x0af00000 0 0x20000>;
			#clock-cells = <1>;
			#reset-cells = <1>;
			#power-domain-cells = <1>;
		};

		mdss: mdss@ae00000 {
			compatible = "qcom,sdm845-mdss";
			reg = <0 0x0ae00000 0 0x1000>;
			reg-names = "mdss";

			interconnects = <&gem_noc MASTER_AMPSS_M0 &config_noc SLAVE_DISPLAY_CFG>,
					<&mmss_noc MASTER_MDP_PORT0 &mc_virt SLAVE_EBI_CH0>,
					<&mmss_noc MASTER_MDP_PORT1 &mc_virt SLAVE_EBI_CH0>;
			interconnect-names = "notused", "mdp0-mem", "mdp1-mem";

			power-domains = <&dispcc MDSS_GDSC>;

			clocks = <&gcc GCC_DISP_AHB_CLK>,
				 <&gcc GCC_DISP_HF_AXI_CLK>,
				 <&gcc GCC_DISP_SF_AXI_CLK>,
				 <&dispcc DISP_CC_MDSS_MDP_CLK>;
			clock-names = "iface", "bus", "nrt_bus", "core";

			assigned-clocks = <&dispcc DISP_CC_MDSS_MDP_CLK>;
			assigned-clock-rates = <300000000>;

			interrupts = <GIC_SPI 83 IRQ_TYPE_LEVEL_HIGH>;
			interrupt-controller;
			#interrupt-cells = <1>;

			iommus = <&apps_smmu 0x800 0x420>;

			status = "disabled";

			#address-cells = <2>;
			#size-cells = <2>;
			ranges;

			mdss_mdp: mdp@ae01000 {
				compatible = "qcom,sdm845-dpu";
				reg = <0 0x0ae01000 0 0x8f000>,
				      <0 0x0aeb0000 0 0x2008>;
				reg-names = "mdp", "vbif";

				clocks = <&dispcc DISP_CC_MDSS_AHB_CLK>,
					 <&dispcc DISP_CC_MDSS_MDP_CLK>,
					 <&dispcc DISP_CC_MDSS_VSYNC_CLK>;
				clock-names = "iface", "core", "vsync";

				assigned-clocks = <&dispcc DISP_CC_MDSS_MDP_CLK>,
						  <&dispcc DISP_CC_MDSS_VSYNC_CLK>;
				assigned-clock-rates = <300000000>,
						       <19200000>;

				interrupt-parent = <&mdss>;
				interrupts = <0 IRQ_TYPE_LEVEL_HIGH>;

				status = "disabled";

				ports {
					#address-cells = <1>;
					#size-cells = <0>;

					port@0 {
						reg = <0>;
						dpu_intf0_out: endpoint {
							remote-endpoint = <&dp_in>;
						};
					};

					port@1 {
						reg = <1>;
						dpu_intf1_out: endpoint {
							remote-endpoint = <&dsi0_in>;
						};
					};

					port@2 {
						reg = <2>;
						dpu_intf2_out: endpoint {
							remote-endpoint = <&dsi1_in>;
						};
					};
				};
			};

			dsi0: dsi@ae94000 {
				compatible = "qcom,mdss-dsi-ctrl";
				reg = <0 0x0ae94000 0 0x400>;
				reg-names = "dsi_ctrl";

				interrupt-parent = <&mdss>;
				interrupts = <4 IRQ_TYPE_LEVEL_HIGH>;

				clocks = <&dispcc DISP_CC_MDSS_BYTE0_CLK>,
					 <&dispcc DISP_CC_MDSS_BYTE0_INTF_CLK>,
					 <&dispcc DISP_CC_MDSS_PCLK0_CLK>,
					 <&dispcc DISP_CC_MDSS_ESC0_CLK>,
					 <&dispcc DISP_CC_MDSS_AHB_CLK>;
				clock-names = "byte",
					      "byte_intf",
					      "pixel",
					      "core",
					      "iface";

				phys = <&dsi0_phy>;
				phy-names = "dsi";

				status = "disabled";

				ports {
					#address-cells = <1>;
					#size-cells = <0>;

					port@0 {
						reg = <0>;
						dsi0_in: endpoint {
							remote-endpoint = <&dpu_intf1_out>;
						};
					};

					port@1 {
						reg = <1>;
						dsi0_out: endpoint {
						};
					};
				};
			};

			dsi0_phy: dsi-phy@ae94400 {
				compatible = "qcom,dsi-phy-7nm";
				reg = <0 0x0ae94400 0 0x200>,
				      <0 0x0ae94600 0 0x280>,
				      <0 0x0ae94900 0 0x260>;
				reg-names = "dsi_phy",
					    "dsi_phy_lane",
					    "dsi_pll";

				#clock-cells = <1>;
				#phy-cells = <0>;

				clocks = <&dispcc DISP_CC_MDSS_AHB_CLK>,
					 <&rpmhcc RPMH_CXO_CLK>;
				clock-names = "iface", "ref";

				status = "disabled";
			};

			dsi1: dsi@ae96000 {
				compatible = "qcom,mdss-dsi-ctrl";
				reg = <0 0x0ae96000 0 0x400>;
				reg-names = "dsi_ctrl";

				interrupt-parent = <&mdss>;
				interrupts = <5 IRQ_TYPE_LEVEL_HIGH>;

				clocks = <&dispcc DISP_CC_MDSS_BYTE1_CLK>,
					 <&dispcc DISP_CC_MDSS_BYTE1_INTF_CLK>,
					 <&dispcc DISP_CC_MDSS_PCLK1_CLK>,
					 <&dispcc DISP_CC_MDSS_ESC1_CLK>,
					 <&dispcc DISP_CC_MDSS_AHB_CLK>;
				clock-names = "byte",
					      "byte_intf",
					      "pixel",
					      "core",
					      "iface";

				phys = <&dsi1_phy>;
				phy-names = "dsi";

				status = "disabled";

				ports {
					#address-cells = <1>;
					#size-cells = <0>;

					port@0 {
						reg = <0>;
						dsi1_in: endpoint {
							remote-endpoint = <&dpu_intf2_out>;
						};
					};

					port@1 {
						reg = <1>;
						dsi1_out: endpoint {
						};
					};
				};
			};

			dsi1_phy: dsi-phy@ae96400 {
				compatible = "qcom,dsi-phy-7nm";
				reg = <0 0x0ae96400 0 0x200>,
				      <0 0x0ae96600 0 0x280>,
				      <0 0x0ae96900 0 0x260>;
				reg-names = "dsi_phy",
					    "dsi_phy_lane",
					    "dsi_pll";

				#clock-cells = <1>;
				#phy-cells = <0>;

				clocks = <&dispcc DISP_CC_MDSS_AHB_CLK>,
					 <&rpmhcc RPMH_CXO_CLK>;
				clock-names = "iface", "ref";

				status = "disabled";
			};


			msm_dp: dp_display@ae90000{
				cell-index = <0>;
				compatible = "qcom,dp-display";

				reg =   <0 0xae90000 0 0x0dc>,
					<0 0xae90200 0 0x0c0>,
					<0 0xae90400 0 0x508>,
					<0 0xae90a00 0 0x094>,
					<0 0x88eaa00 0 0x200>,
					<0 0x88ea200 0 0x200>,
					<0 0x88ea600 0 0x200>,
					<0 0xaf02000 0 0x1a0>,
					<0 0x780000 0 0x621c>,
					<0 0x88ea040 0 0x10>,
					<0 0x88e8000 0 0x20>,
					<0 0x0aee1000 0 0x034>,
					<0 0xae91000 0 0x094>;
				reg-names = "dp_ahb", "dp_aux", "dp_link",
					"dp_p0", "dp_phy", "dp_ln_tx0", "dp_ln_tx1",
					"dp_mmss_cc", "qfprom_physical", "dp_pll",
					"usb3_dp_com", "hdcp_physical", "dp_p1";

				interrupt-parent = <&mdss>;
				interrupts = <12 0>;

				extcon = <&usb_1_ssphy>;
				qcom,dp-usbpd-detection = <&pm8150b_pdphy>;

				clocks =  <&dispcc DISP_CC_MDSS_DP_AUX_CLK>,
					<&rpmhcc RPMH_CXO_CLK>,
					<&gcc GCC_USB3_PRIM_CLKREF_CLK>,
					<&gcc GCC_USB3_PRIM_PHY_PIPE_CLK>,
					<&dispcc DISP_CC_MDSS_DP_LINK_CLK>,
					<&dispcc DISP_CC_MDSS_DP_LINK_INTF_CLK>,
					<&dispcc DISP_CC_MDSS_DP_PIXEL_CLK>,
					<&dispcc DISP_CC_MDSS_DP_CRYPTO_CLK>,
					<&dispcc DISP_CC_MDSS_DP_PIXEL_CLK_SRC>;
				clock-names = "core_aux_clk", "core_ref_clk_src",
					"core_usb_ref_clk", "core_usb_pipe_clk",
					"ctrl_link_clk", "ctrl_link_iface_clk",
					"ctrl_pixel_clk", "crypto_clk", "pixel_clk_rcg";

				pll-node = <&dp_pll>;
				qcom,aux-cfg0-settings = [20 00];
				qcom,aux-cfg1-settings = [24 13];
				qcom,aux-cfg2-settings = [28 24];
				qcom,aux-cfg3-settings = [2c 00];
				qcom,aux-cfg4-settings = [30 0a];
				qcom,aux-cfg5-settings = [34 26];
				qcom,aux-cfg6-settings = [38 0a];
				qcom,aux-cfg7-settings = [3c 03];
				qcom,aux-cfg8-settings = [40 bb];
				qcom,aux-cfg9-settings = [44 03];

				qcom,max-pclk-frequency-khz = <675000>;

				qcom,ctrl-supply-entries {
					#address-cells = <1>;
					#size-cells = <0>;

					qcom,ctrl-supply-entry@0 {
						reg = <0>;
						qcom,supply-name = "vdda-1p2";
						qcom,supply-min-voltage = <1200000>;
						qcom,supply-max-voltage = <1200000>;
						qcom,supply-enable-load = <21800>;
						qcom,supply-disable-load = <4>;
					};
				};

				qcom,phy-supply-entries {
					#address-cells = <1>;
					#size-cells = <0>;

					qcom,phy-supply-entry@0 {
						reg = <0>;
						qcom,supply-name = "vdda-0p9";
						qcom,supply-min-voltage = <880000>;
						qcom,supply-max-voltage = <880000>;
						qcom,supply-enable-load = <36000>;
						qcom,supply-disable-load = <32>;
					};
				};

				ports {
					#address-cells = <1>;
					#size-cells = <0>;

					port@0 {
						reg = <0>;
						dp_in: endpoint {
							remote-endpoint = <&dpu_intf0_out>;
						};
					};

					port@1 {
						reg = <1>;
						dp_out: endpoint {
						};
					};
				};
			};

			dp_pll: dp-pll@c011000 {
				compatible = "qcom,dp-pll-10nm";
				label = "DP PLL";
				cell-index = <0>;
				#clock-cells = <1>;

				reg = 	<0 0x088ea000 0 0x200>,
					<0 0x088eaa00 0 0x200>,
					<0 0x088ea200 0 0x200>,
					<0 0x088ea600 0 0x200>,
					<0 0xaf03000 0 0x8>;
				reg-names = "pll_base", "phy_base", "ln_tx0_base",
					"ln_tx1_base", "gdsc_base";

				clocks = <&dispcc DISP_CC_MDSS_AHB_CLK>,
					<&gcc GCC_USB3_PRIM_CLKREF_CLK>,
					<&gcc GCC_USB3_PRIM_PHY_PIPE_CLK>;
				clock-names = "iface_clk", "ref_clk", "pipe_clk";
				clock-rate = <0>;
			};
		};

		wifi: wifi@18800000 {
			compatible = "qcom,wcn3990-wifi";
			reg = <0 0x18800000 0 0x800000>;
			reg-names = "membase";
			memory-region = <&wlan_mem>;
			clock-names = "cxo_ref_clk_pin";
			clocks = <&rpmhcc RPMH_RF_CLK2>;
			interrupts =
				<GIC_SPI 414 IRQ_TYPE_LEVEL_HIGH>,
				<GIC_SPI 415 IRQ_TYPE_LEVEL_HIGH>,
				<GIC_SPI 416 IRQ_TYPE_LEVEL_HIGH>,
				<GIC_SPI 417 IRQ_TYPE_LEVEL_HIGH>,
				<GIC_SPI 418 IRQ_TYPE_LEVEL_HIGH>,
				<GIC_SPI 419 IRQ_TYPE_LEVEL_HIGH>,
				<GIC_SPI 420 IRQ_TYPE_LEVEL_HIGH>,
				<GIC_SPI 421 IRQ_TYPE_LEVEL_HIGH>,
				<GIC_SPI 422 IRQ_TYPE_LEVEL_HIGH>,
				<GIC_SPI 423 IRQ_TYPE_LEVEL_HIGH>,
				<GIC_SPI 424 IRQ_TYPE_LEVEL_HIGH>,
				<GIC_SPI 425 IRQ_TYPE_LEVEL_HIGH>;
			iommus = <&apps_smmu 0x0640 0x1>;
			status = "disabled";
		};
	};

	timer {
		compatible = "arm,armv8-timer";
		interrupts = <GIC_PPI 1 IRQ_TYPE_LEVEL_LOW>,
			     <GIC_PPI 2 IRQ_TYPE_LEVEL_LOW>,
			     <GIC_PPI 3 IRQ_TYPE_LEVEL_LOW>,
			     <GIC_PPI 0 IRQ_TYPE_LEVEL_LOW>;
	};
};
